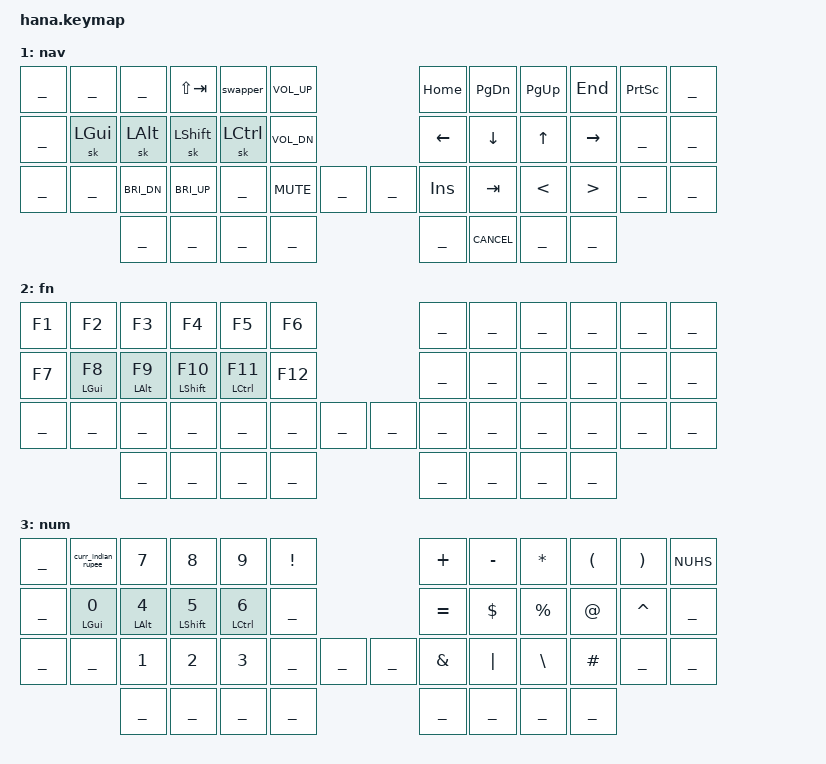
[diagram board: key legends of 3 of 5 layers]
/*
 * Copyright (c) 2020 The ZMK Contributors
 *
 * SPDX-License-Identifier: MIT
 */

#include <behaviors.dtsi>
#include <dt-bindings/zmk/keys.h>
#include <dt-bindings/zmk/bt.h>
#include <dt-bindings/zmk/outputs.h>

#include "zmk-helpers/helper.h"
#include "zmk-helpers/key-labels/hillside46.h"
#include "zmk-helpers/unicode-chars/currency.dtsi"

/* Layers */
#define DEF 0
#define NAV 1
#define FN 2
#define NUM 3
#define SYS 4

// Extra thumb keys used in HRM (not-available in hana)
#define LH5
#define RH5

// #include "mouse.dtsi"
#include "combos.dtsi"
#include "behave.dtsi"

// tap: media next | double-tap: media previous
ZMK_TAP_DANCE(l_rot,
    tapping-term-ms = <250>;
    bindings = <&kp C_NEXT>, <&kp C_PREV>;
)

// tap: play/pause | double-tap: mute
ZMK_TAP_DANCE(r_rot,
    tapping-term-ms = <250>;
    bindings = <&kp C_PP>, <&kp C_MUTE>;
)

/* Keymap */

ZMK_CONDITIONAL_LAYER(sys, NAV NUM, SYS)  // NAV + NUM --> SYS

ZMK_LAYER(base,
//╭─────────────┬─────────────┬─────────────┬─────────────┬─────────────┬─────────────╮                   ╭─────────────┬─────────────┬─────────────┬─────────────┬─────────────┬─────────────╮
    &kp GRAVE     &kp Q         &kp W         &kp E         &kp R         &kp T                             &kp Y         &kp U         &kp I         &kp O         &kp P           &kp LBKT
//├─────────────┼─────────────┼─────────────┼─────────────┼─────────────┼─────────────┤                   ├─────────────┼─────────────┼─────────────┼─────────────┼─────────────┼─────────────┤
    &kp TAB       &hml LGUI A   &hml LALT S   &hml LSHFT D  &hml LCTRL F  &kp G                             &kp H         &hmr LCTRL J  &hmr RSHFT K  &hmr LALT L   &hmr LGUI SEMI  &kp APOS
//├─────────────┼─────────────┼─────────────┼─────────────┼─────────────┼─────────────┤ ╭──────╮ ╭──────╮ ├─────────────┼─────────────┼─────────────┼─────────────┼─────────────┼─────────────┤
    &kp RBKT      &kp Z         &kp X         &kp C         &kp V         &kp B          &l_rot   &r_rot    &kp N         &kp M         &kp COMMA     &kp DOT       &kp FSLH        &kp MINUS
//╰─────────────┴─────────────┼─────────────┼─────────────┼─────────────┼─────────────┤ ╰──────╯ ╰──────╯ ├─────────────┼─────────────┼─────────────┼─────────────┼─────────────┴─────────────╯
                                &kp C_AC_COPY SMART_NUM     &kp ESC       &lt NAV RET                       &kp SPACE     &kp BSPC      &kp DEL       &kp C_AC_PASTE
//                            ╰─────────────┴─────────────┴─────────────┴─────────────╯                   ╰─────────────┴─────────────┴─────────────┴─────────────╯
  , &inc_dec_kp PG_UP PG_DN &inc_dec_kp C_VOL_UP C_VOL_DN
)

ZMK_LAYER(nav,
//╭─────────────┬─────────────┬─────────────┬─────────────┬─────────────┬─────────────╮                   ╭─────────────┬─────────────┬─────────────┬─────────────┬─────────────┬─────────────╮
    ___           ___           ___           &kp LS(TAB)   &swapper      &kp C_VOL_UP                      &kp HOME      &kp PG_DN     &kp PG_UP     &kp END       &kp PSCRN     ___
//├─────────────┼─────────────┼─────────────┼─────────────┼─────────────┼─────────────┤                   ├─────────────┼─────────────┼─────────────┼─────────────┼─────────────┼─────────────┤
    ___           &sk LGUI      &sk LALT      &sk LSHFT     &sk LCTRL     &kp C_VOL_DN                      &kp LEFT      &kp DOWN      &kp UP        &kp RIGHT     ___           ___
//├─────────────┼─────────────┼─────────────┼─────────────┼─────────────┼─────────────┤ ╭──────╮ ╭──────╮ ├─────────────┼─────────────┼─────────────┼─────────────┼─────────────┼─────────────┤
    ___           ___           &kp C_BRI_DN  &kp C_BRI_UP  ___           &kp C_MUTE      ___      ___      &kp INS       &kp TAB       &kp LT        &kp GT        ___           ___
//╰─────────────┴─────────────┼─────────────┼─────────────┼─────────────┼─────────────┤ ╰──────╯ ╰──────╯ ├─────────────┼─────────────┼─────────────┼─────────────┼─────────────┴─────────────╯
                                ___           ___           ___           ___                               ___           CANCEL        ___           ___
//                            ╰─────────────┴─────────────┴─────────────┴─────────────╯                   ╰─────────────┴─────────────┴─────────────┴─────────────╯
)

ZMK_LAYER(fn,
//╭─────────────┬─────────────┬─────────────┬─────────────┬─────────────┬─────────────╮                   ╭─────────────┬─────────────┬─────────────┬─────────────┬─────────────┬─────────────╮
    &kp F1        &kp F2        &kp F3        &kp F4         &kp F5         &kp F6                          ___           ___           ___           ___           ___           ___
//├─────────────┼─────────────┼─────────────┼─────────────┼─────────────┼─────────────┤                   ├─────────────┼─────────────┼─────────────┼─────────────┼─────────────┼─────────────┤
    &kp F7        &hml LGUI F8  &hml LALT F9  &hml LSHFT F10 &hml LCTRL F11 &kp F12                         ___           ___           ___           ___           ___           ___   
//├─────────────┼─────────────┼─────────────┼─────────────┼─────────────┼─────────────┤ ╭──────╮ ╭──────╮ ├─────────────┼─────────────┼─────────────┼─────────────┼─────────────┼─────────────┤
    ___           ___           ___           ___           ___           ___             ___      ___      ___           ___           ___           ___           ___           ___
//╰─────────────┴─────────────┼─────────────┼─────────────┼─────────────┼─────────────┤ ╰──────╯ ╰──────╯ ├─────────────┼─────────────┼─────────────┼─────────────┼─────────────┴─────────────╯
                                ___           ___           ___           ___                               ___           ___           ___           ___
//                            ╰─────────────┴─────────────┴─────────────┴─────────────╯                   ╰─────────────┴─────────────┴─────────────┴─────────────╯
)

ZMK_LAYER(num,
//╭─────────────┬─────────────┬─────────────┬─────────────┬─────────────┬─────────────╮                   ╭─────────────┬─────────────┬─────────────┬─────────────┬─────────────┬─────────────╮
    ___       &curr_indian_rupee &kp N7        &kp N8        &kp N9        &kp EXCL                         &kp PLUS      &kp MINUS     &kp ASTRK     &kp LPAR      &kp RPAR       &kp NUHS
//├─────────────┼─────────────┼─────────────┼─────────────┼─────────────┼─────────────┤                   ├─────────────┼─────────────┼─────────────┼─────────────┼─────────────┼─────────────┤
    ___           &hml LGUI N0   &hml LALT N4  &hml LSHFT N5 &hml LCTRL N6 ___                              &kp EQUAL     &kp DLLR     &kp PRCNT     &kp AT        &kp CARET      ___
//├─────────────┼─────────────┼─────────────┼─────────────┼─────────────┼─────────────┤ ╭──────╮ ╭──────╮ ├─────────────┼─────────────┼─────────────┼─────────────┼─────────────┼─────────────┤
    ___           ___           &kp N1        &kp N2        &kp N3         ___            ___      ___      &kp AMPS      &kp PIPE     &kp BSLH      &kp HASH          ___           ___
//╰─────────────┴─────────────┼─────────────┼─────────────┼─────────────┼─────────────┤ ╰──────╯ ╰──────╯ ├─────────────┼─────────────┼─────────────┼─────────────┼─────────────┴─────────────╯
                                ___           ___           ___            ___                              ___           ___           ___           ___
//                            ╰─────────────┴─────────────┴─────────────┴─────────────╯                   ╰─────────────┴─────────────┴─────────────┴─────────────╯
)

ZMK_LAYER(sys,
//╭─────────────┬─────────────┬─────────────┬─────────────┬─────────────┬─────────────╮                   ╭─────────────┬─────────────┬─────────────┬─────────────┬─────────────┬─────────────╮
    BLE_C(0)      BLE_C(1)      BLE_C(2)      BLE_C(3)      BLE_C(4)      &bt BT_CLR                        &bt BT_CLR_ALL BLE_D(4)     BLE_D(3)      BLE_D(2)      BLE_D(1)      BLE_D(0)
//├─────────────┼─────────────┼─────────────┼─────────────┼─────────────┼─────────────┤                   ├─────────────┼─────────────┼─────────────┼─────────────┼─────────────┼─────────────┤
    ___           ___           ___           ___           &soft_off     &bootloader                       &bootloader    &soft_off    ___           ___
//├─────────────┼─────────────┼─────────────┼─────────────┼─────────────┼─────────────┤ ╭──────╮ ╭──────╮ ├─────────────┼─────────────┼─────────────┼─────────────┼─────────────┼─────────────┤
    ___           ___           ___           ___           ___           &sys_reset      ___      ___      &sys_reset     ___          ___           ___           ___           ___
//╰─────────────┴─────────────┼─────────────┼─────────────┼─────────────┼─────────────┤ ╰──────╯ ╰──────╯ ├─────────────┼─────────────┼─────────────┼─────────────┼─────────────┴─────────────╯
                                &out OUT_BLE  &out OUT_USB  ___           ___                               ___            ___          &out OUT_USB  &out OUT_BLE
//                            ╰─────────────┴─────────────┴─────────────┴─────────────╯                   ╰─────────────┴─────────────┴─────────────┴─────────────╯
)

// ZMK_LAYER(uc,
// //╭──────╮ ╭─────────────┬─────────────┬─────────────┬─────────────┬─────────────╮ ╭──────╮ ╭─────────────┬─────────────┬─────────────┬─────────────┬─────────────╮ ╭──────╮
//     X_LT     ___           &el_omega     &el_phi       &el_pi        &el_beta        X_MT     ___           &el_lambda    &el_upsilon   &el_psi       &de_eszett      X_RT
// //├──────┤ ├─────────────┼─────────────┼─────────────┼─────────────┼─────────────┤ ├──────┤ ├─────────────┼─────────────┼─────────────┼─────────────┼─────────────┤ ├──────┤
//     X_LM     &el_alpha     &el_rho       &el_sigma     &el_tau       &el_gamma       X_MM     &el_mu        &el_nu        &el_epsilon   &el_iota      &el_omikron     X_RM
// //├──────┤ ├─────────────┼─────────────┼─────────────┼─────────────┼─────────────┤ ├──────┤ ├─────────────┼─────────────┼─────────────┼─────────────┼─────────────┤ ├──────┤
//     X_LB     &el_zeta      &el_xi        &el_chi       &el_delta     &el_theta       X_MB     &el_kappa     &el_eta       &de_ae        &de_oe        &de_ue          X_RB
// //├──────┤ ╰─────────────┼─────────────┴─────────────┼─────────────┼─────────────┤ ├──────┤ ├─────────────┼─────────────┼─────────────┴───────────────────────────╯ ├──────┤
//     X_LH                                               ___           ___             X_MH     ___           ___                                                       X_RH
// //╰──────╯                                           ╰─────────────┴─────────────╯ ╰──────╯ ╰───────────────────────────╯                                           ╰──────╯
// )

// ZMK_LAYER(mouse,
// //╭──────╮ ╭─────────────┬─────────────┬─────────────┬─────────────┬─────────────╮ ╭──────╮ ╭─────────────┬─────────────┬─────────────┬─────────────┬─────────────╮ ╭──────╮
//     X_LT     ___           ___           ___           ___           ___             X_MT     U_WH_L        U_WH_D        U_MS_U         U_WH_U       U_WH_R          X_RT
// //├──────┤ ├─────────────┼─────────────┼─────────────┼─────────────┼─────────────┤ ├──────┤ ├─────────────┼─────────────┼─────────────┼─────────────┼─────────────┤ ├──────┤
//     X_LM     ___           ___           ___           ___           ___             X_MM     ___           U_MS_L        U_MS_D         U_MS_R       ___             X_RM
// //├──────┤ ├─────────────┼─────────────┼─────────────┼─────────────┼─────────────┤ ├──────┤ ├─────────────┼─────────────┼─────────────┼─────────────┼─────────────┤ ├──────┤
//     X_LB     ___           ___           ___           ___           ___             X_MB     ___           &mkp MB4      &mkp MCLK      &mkp MB5     ___             X_RB
// //├──────┤ ╰─────────────┼─────────────┴─────────────┼─────────────┼─────────────┤ ├──────┤ ├─────────────┼─────────────┼─────────────┴───────────────────────────╯ ├──────┤
//     X_LH                                               ___           ___             X_MH     &mkp LCLK     &mkp RCLK                                                 X_RH
// //╰──────╯                                           ╰─────────────┴─────────────╯ ╰──────╯ ╰─────────────┴─────────────╯                                           ╰──────╯
// )
